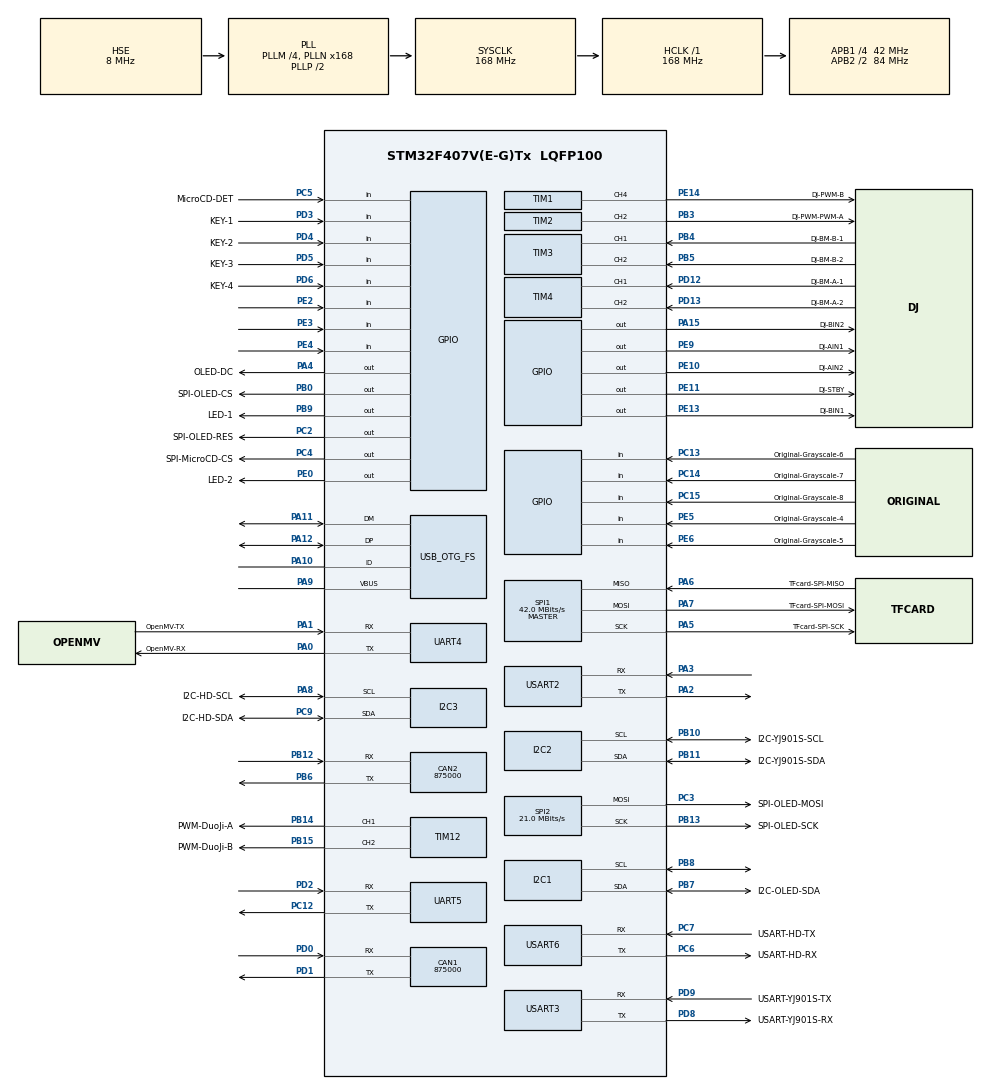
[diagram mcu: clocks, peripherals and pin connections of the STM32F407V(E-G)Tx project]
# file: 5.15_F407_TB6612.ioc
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CAN1.CalculateBaudRate=875000
CAN1.CalculateTimeBit=1142
CAN1.CalculateTimeQuantum=380.95238095238096
CAN2.CalculateBaudRate=875000
CAN2.CalculateTimeBit=1142
CAN2.CalculateTimeQuantum=380.95238095238096
Mcu.Family=STM32F4
Mcu.Name=STM32F407V(E-G)Tx
Mcu.Package=LQFP100
NVIC.PriorityGroup=NVIC_PRIORITYGROUP_4
PA0-WKUP.GPIO_Label=OpenMV-RX
PA0-WKUP.Mode=Asynchronous
PA0-WKUP.Signal=UART4_TX
PA1.GPIO_Label=OpenMV-TX
PA1.Mode=Asynchronous
PA1.Signal=UART4_RX
PA10.Mode=OTG/Dual_Role_Device
PA10.Signal=USB_OTG_FS_ID
PA11.Mode=OTG/Dual_Role_Device
PA11.Signal=USB_OTG_FS_DM
PA12.Mode=OTG/Dual_Role_Device
PA12.Signal=USB_OTG_FS_DP
PA13.Mode=Serial_Wire
PA13.Signal=SYS_JTMS-SWDIO
PA14.Mode=Serial_Wire
PA14.Signal=SYS_JTCK-SWCLK
PA15.GPIO_Label=DJ-BIN2
PA15.Signal=GPIO_Output
PA2.Mode=Asynchronous
PA2.Signal=USART2_TX
PA3.Mode=Asynchronous
PA3.Signal=USART2_RX
PA4.GPIO_Label=OLED-DC
PA4.Signal=GPIO_Output
PA5.GPIO_Label=TFcard-SPI-SCK
PA5.Mode=Full_Duplex_Master
PA5.Signal=SPI1_SCK
PA6.GPIO_Label=TFcard-SPI-MISO
PA6.Mode=Full_Duplex_Master
PA6.Signal=SPI1_MISO
PA7.GPIO_Label=TFcard-SPI-MOSI
PA7.Mode=Full_Duplex_Master
PA7.Signal=SPI1_MOSI
PA8.GPIO_Label=I2C-HD-SCL
PA8.Mode=I2C
PA8.Signal=I2C3_SCL
PA9.Mode=Activate_VBUS
PA9.Signal=USB_OTG_FS_VBUS
PB0.GPIO_Label=SPI-OLED-CS
PB0.Signal=GPIO_Output
PB10.GPIO_Label=I2C-YJ901S-SCL
PB10.Mode=I2C
PB10.Signal=I2C2_SCL
PB11.GPIO_Label=I2C-YJ901S-SDA
PB11.Mode=I2C
PB11.Signal=I2C2_SDA
PB12.Mode=CAN_Activate
PB12.Signal=CAN2_RX
PB13.GPIO_Label=SPI-OLED-SCK
PB13.Mode=TX_Only_Simplex_Unidirect_Master
PB13.Signal=SPI2_SCK
PB14.GPIO_Label=PWM-DuoJi-A
PB14.Signal=S_TIM12_CH1
PB15.GPIO_Label=PWM-DuoJi-B
PB15.Signal=S_TIM12_CH2
PB3.GPIO_Label=DJ-PWM-PWM-A
PB3.Signal=S_TIM2_CH2
PB4.GPIO_Label=DJ-BM-B-1
PB4.Signal=S_TIM3_CH1
PB5.GPIO_Label=DJ-BM-B-2
PB5.Signal=S_TIM3_CH2
PB6.Mode=CAN_Activate
PB6.Signal=CAN2_TX
PB7.GPIO_Label=I2C-OLED-SDA
PB7.Mode=I2C
PB7.Signal=I2C1_SDA
PB8.Mode=I2C
PB8.Signal=I2C1_SCL
PB9.GPIO_Label=LED-1
PB9.Signal=GPIO_Output
PC12.Mode=Asynchronous
PC12.Signal=UART5_TX
PC13-ANTI_TAMP.GPIO_Label=Original-Grayscale-6
PC13-ANTI_TAMP.Signal=GPIO_Input
PC14-OSC32_IN.GPIO_Label=Original-Grayscale-7
PC14-OSC32_IN.Signal=GPIO_Input
PC15-OSC32_OUT.GPIO_Label=Original-Grayscale-8
PC15-OSC32_OUT.Signal=GPIO_Input
PC2.GPIO_Label=SPI-OLED-RES
PC2.Signal=GPIO_Output
PC3.GPIO_Label=SPI-OLED-MOSI
PC3.Mode=TX_Only_Simplex_Unidirect_Master
PC3.Signal=SPI2_MOSI
PC4.GPIO_Label=SPI-MicroCD-CS
PC4.Signal=GPIO_Output
PC5.GPIO_Label=MicroCD-DET
PC5.Signal=GPIO_Input
PC6.GPIO_Label=USART-HD-RX
PC6.Mode=Asynchronous
PC6.Signal=USART6_TX
PC7.GPIO_Label=USART-HD-TX
PC7.Mode=Asynchronous
PC7.Signal=USART6_RX
PC9.GPIO_Label=I2C-HD-SDA
PC9.Mode=I2C
PC9.Signal=I2C3_SDA
PD0.Mode=CAN_Activate
PD0.Signal=CAN1_RX
PD1.Mode=CAN_Activate
PD1.Signal=CAN1_TX
PD12.GPIO_Label=DJ-BM-A-1
PD12.Signal=S_TIM4_CH1
PD13.GPIO_Label=DJ-BM-A-2
PD13.Signal=S_TIM4_CH2
PD2.Mode=Asynchronous
PD2.Signal=UART5_RX
PD3.GPIO_Label=KEY-1
PD3.Signal=GPIO_Input
PD4.GPIO_Label=KEY-2
PD4.Signal=GPIO_Input
PD5.GPIO_Label=KEY-3
PD5.Signal=GPIO_Input
PD6.GPIO_Label=KEY-4
PD6.Signal=GPIO_Input
PD8.GPIO_Label=USART-YJ901S-RX
PD8.Mode=Asynchronous
PD8.Signal=USART3_TX
PD9.GPIO_Label=USART-YJ901S-TX
PD9.Mode=Asynchronous
PD9.Signal=USART3_RX
PE0.GPIO_Label=LED-2
PE0.Signal=GPIO_Output
PE10.GPIO_Label=DJ-AIN2
PE10.Signal=GPIO_Output
PE11.GPIO_Label=DJ-STBY
PE11.Signal=GPIO_Output
PE13.GPIO_Label=DJ-BIN1
PE13.Signal=GPIO_Output
PE14.GPIO_Label=DJ-PWM-B
PE14.Signal=S_TIM1_CH4
PE2.Signal=GPIO_Input
PE3.Signal=GPIO_Input
PE4.Signal=GPIO_Input
PE5.GPIO_Label=Original-Grayscale-4
PE5.Signal=GPIO_Input
PE6.GPIO_Label=Original-Grayscale-5
PE6.Signal=GPIO_Input
PE9.GPIO_Label=DJ-AIN1
PE9.Signal=GPIO_Output
PH0-OSC_IN.Mode=HSE-External-Oscillator
PH0-OSC_IN.Signal=RCC_OSC_IN
PH1-OSC_OUT.Mode=HSE-External-Oscillator
PH1-OSC_OUT.Signal=RCC_OSC_OUT
ProjectManager.HeapSize=0x200
ProjectManager.StackSize=0x400
ProjectManager.TargetToolchain=MDK-ARM V5.32
RCC.48MHZClocksFreq_Value=48000000
RCC.AHBFreq_Value=168000000
RCC.APB1CLKDivider=RCC_HCLK_DIV4
RCC.APB1Freq_Value=42000000
RCC.APB1TimFreq_Value=84000000
RCC.APB2CLKDivider=RCC_HCLK_DIV2
RCC.APB2Freq_Value=84000000
RCC.APB2TimFreq_Value=168000000
RCC.CortexFreq_Value=168000000
RCC.HCLKFreq_Value=168000000
RCC.HSE_VALUE=8000000
RCC.HSI_VALUE=16000000
RCC.LSE_VALUE=32768
RCC.PLLM=4
RCC.PLLN=168
RCC.PLLQ=7
RCC.SYSCLKFreq_VALUE=168000000
RCC.SYSCLKSource=RCC_SYSCLKSOURCE_PLLCLK
RCC.VCOOutputFreq_Value=336000000
SH.S_TIM12_CH1.0=TIM12_CH1,PWM Generation1 CH1
SH.S_TIM12_CH2.0=TIM12_CH2,PWM Generation2 CH2
SH.S_TIM1_CH4.0=TIM1_CH4,PWM Generation4 CH4
SH.S_TIM2_CH2.0=TIM2_CH2,PWM Generation2 CH2
SH.S_TIM3_CH1.0=TIM3_CH1,Encoder_Interface
SH.S_TIM3_CH2.0=TIM3_CH2,Encoder_Interface
SH.S_TIM4_CH1.0=TIM4_CH1,Encoder_Interface
SH.S_TIM4_CH2.0=TIM4_CH2,Encoder_Interface
SPI1.CalculateBaudRate=42.0 MBits/s
SPI1.Direction=SPI_DIRECTION_2LINES
SPI1.Mode=SPI_MODE_MASTER
SPI1.VirtualType=VM_MASTER
SPI2.CalculateBaudRate=21.0 MBits/s
SPI2.Direction=SPI_DIRECTION_2LINES
SPI2.Mode=SPI_MODE_MASTER
SPI2.VirtualType=VM_MASTER
TIM1.AutoReloadPreload=TIM_AUTORELOAD_PRELOAD_ENABLE
TIM1.Channel-PWM\ Generation4\ CH4=TIM_CHANNEL_4
TIM1.Period=1049
TIM1.Prescaler=7
TIM12.Channel-PWM\ Generation1\ CH1=TIM_CHANNEL_1
TIM12.Channel-PWM\ Generation2\ CH2=TIM_CHANNEL_2
TIM2.Channel-PWM\ Generation2\ CH2=TIM_CHANNEL_2
UART4.VirtualMode=Asynchronous
UART5.VirtualMode=Asynchronous
USART2.VirtualMode=VM_ASYNC
USART3.VirtualMode=VM_ASYNC
USART6.VirtualMode=VM_ASYNC
board=custom

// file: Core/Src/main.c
/* USER CODE BEGIN Header */
/**
  ******************************************************************************
  * @file           : main.c
  * @brief          : Main program body
  ******************************************************************************
  * @attention
  *
  * Copyright (c) 2026 STMicroelectronics.
  * All rights reserved.
  *
  * This software is licensed under terms that can be found in the LICENSE file
  * in the root directory of this software component.
  * If no LICENSE file comes with this software, it is provided AS-IS.
  *
  ******************************************************************************
  */
/* USER CODE END Header */
#include "main.h"
#include "can.h"
#include "i2c.h"
#include "spi.h"
#include "tim.h"
#include "usart.h"
#include "usb_otg.h"
#include "gpio.h"

/* USER CODE BEGIN Includes */
#include "gimbal_tracker.h"
#include "openmv_vision.h"
#include "x42s_gimbal_app.h"

/* USER CODE END Includes */

void SystemClock_Config(void);

int main(void)
{

  /* MCU Configuration--------------------------------------------------------*/

  /* Reset of all peripherals, Initializes the Flash interface and the Systick. */
  HAL_Init();

  /* Configure the system clock */
  SystemClock_Config();

  /* Initialize all configured peripherals */
  MX_GPIO_Init();
  MX_I2C1_Init();
  MX_I2C2_Init();
  MX_I2C3_Init();
  MX_SPI1_Init();
  MX_SPI2_Init();
  MX_TIM1_Init();
  MX_TIM2_Init();
  MX_TIM3_Init();
  MX_TIM4_Init();
  MX_TIM12_Init();
  MX_UART4_Init();
  MX_UART5_Init();
  MX_USART3_UART_Init();
  MX_USART6_UART_Init();
  MX_USB_OTG_FS_USB_Init();
  MX_CAN1_Init();
  MX_CAN2_Init();
  MX_USART2_UART_Init();
  /* USER CODE BEGIN 2 */
  if (OpenMVVision_Init() != HAL_OK)
  {
    Error_Handler();
  }

  if (X42sGimbalApp_Init() != HAL_OK)
  {
    Error_Handler();
  }

  if (GimbalTracker_Init() != HAL_OK)
  {
    Error_Handler();
  }

  /* USER CODE END 2 */

  /* Infinite loop */
  while (1)
  {

    /* USER CODE BEGIN 3 */
    OpenMVVision_Poll(HAL_GetTick());
    X42sGimbalApp_Poll();
    GimbalTracker_Poll(HAL_GetTick());
  }
  /* USER CODE END 3 */
}

void SystemClock_Config(void)
{
  RCC_OscInitTypeDef RCC_OscInitStruct = {0};
  RCC_ClkInitTypeDef RCC_ClkInitStruct = {0};

  /** Configure the main internal regulator output voltage
  */
  __HAL_RCC_PWR_CLK_ENABLE();
  __HAL_PWR_VOLTAGESCALING_CONFIG(PWR_REGULATOR_VOLTAGE_SCALE1);

  /** Initializes the RCC Oscillators according to the specified parameters
  * in the RCC_OscInitTypeDef structure.
  */
  RCC_OscInitStruct.OscillatorType = RCC_OSCILLATORTYPE_HSE;
  RCC_OscInitStruct.HSEState = RCC_HSE_ON;
  RCC_OscInitStruct.PLL.PLLState = RCC_PLL_ON;
  RCC_OscInitStruct.PLL.PLLSource = RCC_PLLSOURCE_HSE;
  RCC_OscInitStruct.PLL.PLLM = 4;
  RCC_OscInitStruct.PLL.PLLN = 168;
  RCC_OscInitStruct.PLL.PLLP = RCC_PLLP_DIV2;
  RCC_OscInitStruct.PLL.PLLQ = 7;
  if (HAL_RCC_OscConfig(&RCC_OscInitStruct) != HAL_OK)
  {
    Error_Handler();
  }

  /** Initializes the CPU, AHB and APB buses clocks
  */
  RCC_ClkInitStruct.ClockType = RCC_CLOCKTYPE_HCLK|RCC_CLOCKTYPE_SYSCLK
                              |RCC_CLOCKTYPE_PCLK1|RCC_CLOCKTYPE_PCLK2;
  RCC_ClkInitStruct.SYSCLKSource = RCC_SYSCLKSOURCE_PLLCLK;
  RCC_ClkInitStruct.AHBCLKDivider = RCC_SYSCLK_DIV1;
  RCC_ClkInitStruct.APB1CLKDivider = RCC_HCLK_DIV4;
  RCC_ClkInitStruct.APB2CLKDivider = RCC_HCLK_DIV2;

  if (HAL_RCC_ClockConfig(&RCC_ClkInitStruct, FLASH_LATENCY_5) != HAL_OK)
  {
    Error_Handler();
  }
}

void Error_Handler(void)
{
  __disable_irq();
  while (1)
  {
  }
}
